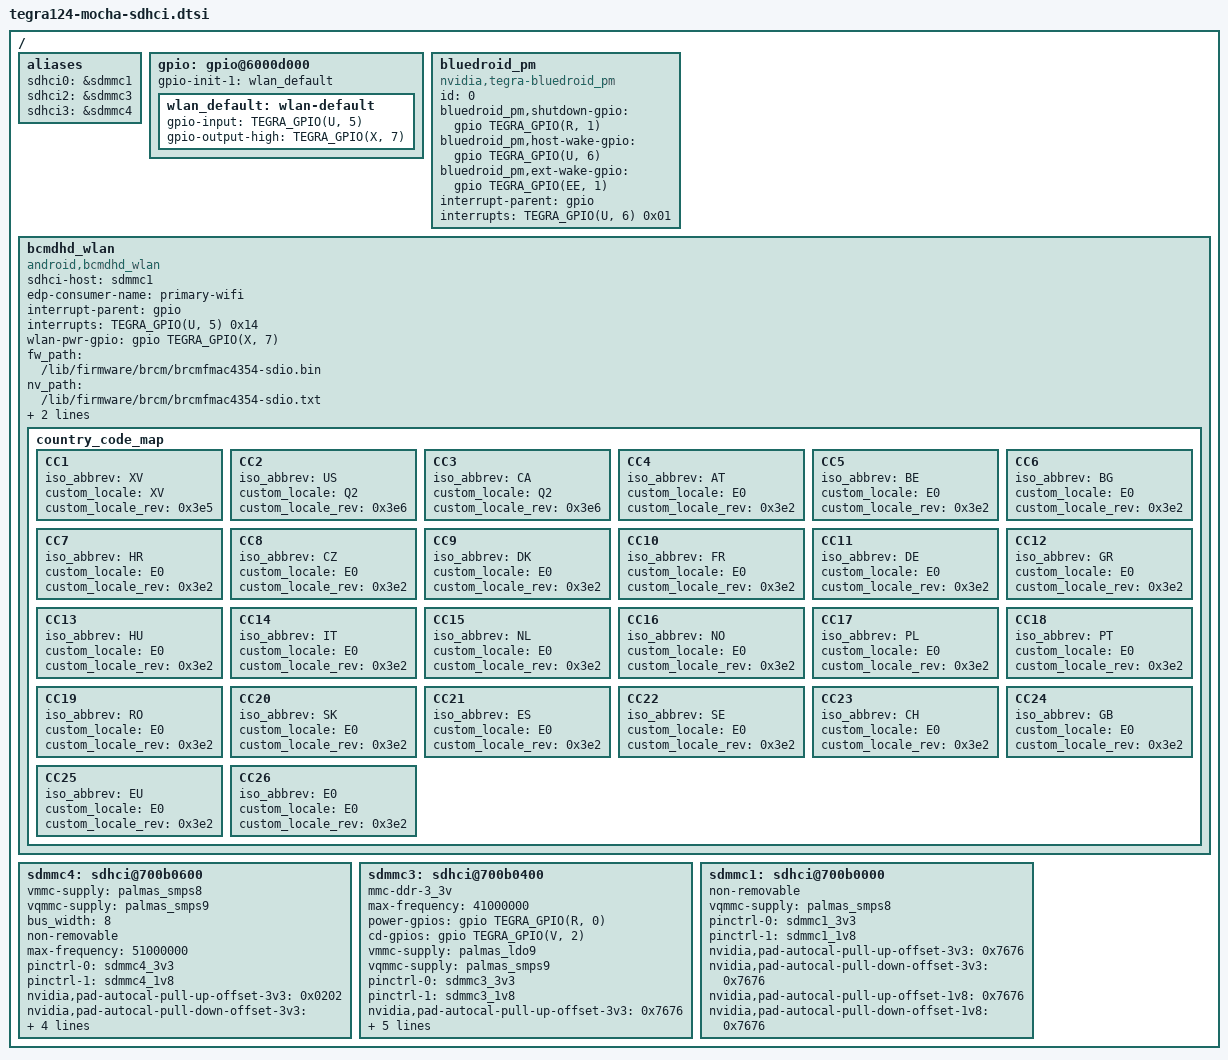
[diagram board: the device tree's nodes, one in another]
/*
 * arch/arm/boot/dts/tegra124-platforms/tegra124-mocha-sdhci.dtsi
 *
 * Copyright (c) 2018, Alexandrov Dmitry. All rights reserved.
 *
 * This program is free software; you can redistribute it and/or modify it
 * under the terms and conditions of the GNU General Public License,
 * version 2, as published by the Free Software Foundation.
 *
 * This program is distributed in the hope it will be useful, but WITHOUT
 * ANY WARRANTY; without even the implied warranty of MERCHANTABILITY or
 * FITNESS FOR A PARTICULAR PURPOSE.  See the GNU General Public License for
 * more details.
 *
 */
 
#include <dt-bindings/gpio/tegra-gpio.h>

/ {
	
 	aliases {
 		sdhci0 = &sdmmc1;
		sdhci2 = &sdmmc3;
		sdhci3 = &sdmmc4;
	};

	gpio: gpio@6000d000 {
		gpio-init-1 = <&wlan_default>;

		wlan_default: wlan-default {
			gpio-input = <
				TEGRA_GPIO(U, 5)
				>;
			gpio-output-high = <
				TEGRA_GPIO(X, 7)
				>;
		};
	};

	bluedroid_pm {
		compatible = "nvidia,tegra-bluedroid_pm";
		id = <0>;
		bluedroid_pm,shutdown-gpio = <&gpio TEGRA_GPIO(R, 1) 0>;
		bluedroid_pm,host-wake-gpio = <&gpio TEGRA_GPIO(U, 6) 0>;
		bluedroid_pm,ext-wake-gpio = <&gpio TEGRA_GPIO(EE, 1) 0>;
		interrupt-parent = <&gpio>;
		interrupts = <TEGRA_GPIO(U, 6) 0x01>;
	};

	bcmdhd_wlan {
		compatible = "android,bcmdhd_wlan";
		sdhci-host = <&sdmmc1>;
		edp-consumer-name = "primary-wifi";
		interrupt-parent = <&gpio>;
		interrupts = <TEGRA_GPIO(U, 5) 0x14>;
		wlan-pwr-gpio = <&gpio TEGRA_GPIO(X, 7) 0>;
		status = "okay";
		fw_path = "/lib/firmware/brcm/brcmfmac4354-sdio.bin";
		nv_path = "/lib/firmware/brcm/brcmfmac4354-sdio.txt";
		mac-address-file = "/lib/firmware/brcm/macaddr.txt";

		country_code_map {

			CC1 {
				iso_abbrev = "XV";
				custom_locale = "XV";
				custom_locale_rev = <0x3e5>;
			};

			CC2 {
				iso_abbrev = "US";
				custom_locale = "Q2";
				custom_locale_rev = <0x3e6>;
			};

			CC3 {
				iso_abbrev = "CA";
				custom_locale = "Q2";
				custom_locale_rev = <0x3e6>;
			};

			CC4 {
				iso_abbrev = "AT";
				custom_locale = "E0";
				custom_locale_rev = <0x3e2>;
			};

			CC5 {
				iso_abbrev = "BE";
				custom_locale = "E0";
				custom_locale_rev = <0x3e2>;
			};

			CC6 {
				iso_abbrev = "BG";
				custom_locale = "E0";
				custom_locale_rev = <0x3e2>;
			};

			CC7 {
				iso_abbrev = "HR";
				custom_locale = "E0";
				custom_locale_rev = <0x3e2>;
			};

			CC8 {
				iso_abbrev = "CZ";
				custom_locale = "E0";
				custom_locale_rev = <0x3e2>;
			};

			CC9 {
				iso_abbrev = "DK";
				custom_locale = "E0";
				custom_locale_rev = <0x3e2>;
			};

			CC10 {
				iso_abbrev = "FR";
				custom_locale = "E0";
				custom_locale_rev = <0x3e2>;
			};

			CC11 {
				iso_abbrev = "DE";
				custom_locale = "E0";
				custom_locale_rev = <0x3e2>;
			};

			CC12 {
				iso_abbrev = "GR";
				custom_locale = "E0";
				custom_locale_rev = <0x3e2>;
			};

			CC13 {
				iso_abbrev = "HU";
				custom_locale = "E0";
				custom_locale_rev = <0x3e2>;
			};

			CC14 {
				iso_abbrev = "IT";
				custom_locale = "E0";
				custom_locale_rev = <0x3e2>;
			};

			CC15 {
				iso_abbrev = "NL";
				custom_locale = "E0";
				custom_locale_rev = <0x3e2>;
			};

			CC16 {
				iso_abbrev = "NO";
				custom_locale = "E0";
				custom_locale_rev = <0x3e2>;
			};

			CC17 {
				iso_abbrev = "PL";
				custom_locale = "E0";
				custom_locale_rev = <0x3e2>;
			};

			CC18 {
				iso_abbrev = "PT";
				custom_locale = "E0";
				custom_locale_rev = <0x3e2>;
			};

			CC19 {
				iso_abbrev = "RO";
				custom_locale = "E0";
				custom_locale_rev = <0x3e2>;
			};

			CC20 {
				iso_abbrev = "SK";
				custom_locale = "E0";
				custom_locale_rev = <0x3e2>;
			};

			CC21 {
				iso_abbrev = "ES";
				custom_locale = "E0";
				custom_locale_rev = <0x3e2>;
			};

			CC22 {
				iso_abbrev = "SE";
				custom_locale = "E0";
				custom_locale_rev = <0x3e2>;
			};

			CC23 {
				iso_abbrev = "CH";
				custom_locale = "E0";
				custom_locale_rev = <0x3e2>;
			};

			CC24 {
				iso_abbrev = "GB";
				custom_locale = "E0";
				custom_locale_rev = <0x3e2>;
			};

			CC25 {
				iso_abbrev = "EU";
				custom_locale = "E0";
				custom_locale_rev = <0x3e2>;
			};

			CC26 {
				iso_abbrev = "E0";
				custom_locale = "E0";
				custom_locale_rev = <0x3e2>;
			};
		};
	};
	
	/* MMC */
 	sdmmc4: sdhci@700b0600 {
		vmmc-supply = <&palmas_smps8>;
		vqmmc-supply = <&palmas_smps9>;
		bus_width = <8>;
		non-removable;
		max-frequency = <51000000>;
		pinctrl-names = "sdmmc-3v3", "sdmmc-1v8";
		pinctrl-0 = <&sdmmc4_3v3>;
		pinctrl-1 = <&sdmmc4_1v8>;
		nvidia,pad-autocal-pull-up-offset-3v3 = <0x0202>;
		nvidia,pad-autocal-pull-down-offset-3v3 = <0x0202>;
		nvidia,pad-autocal-pull-up-offset-1v8 = <0x0202>;
		nvidia,pad-autocal-pull-down-offset-1v8 = <0x0202>;
		status = "okay";
 	};
	
	/* SDcard */
	sdmmc3: sdhci@700b0400 {
		mmc-ddr-3_3v;
		max-frequency = <41000000>;
 		power-gpios = <&gpio TEGRA_GPIO(R, 0) 0>;
 		cd-gpios = <&gpio TEGRA_GPIO(V, 2) 0>;
 		vmmc-supply = <&palmas_ldo9>;
		vqmmc-supply = <&palmas_smps9>;
		pinctrl-names = "sdmmc-3v3", "sdmmc-1v8";
		pinctrl-0 = <&sdmmc3_3v3>;
		pinctrl-1 = <&sdmmc3_1v8>;
		nvidia,pad-autocal-pull-up-offset-3v3 = <0x7676>;
		nvidia,pad-autocal-pull-down-offset-3v3 = <0x7676>;
		nvidia,pad-autocal-pull-up-offset-1v8 = <0x7676>;
		nvidia,pad-autocal-pull-down-offset-1v8 = <0x7676>;
		status = "okay";
	};
	
	/* Wi-Fi */
	sdmmc1: sdhci@700b0000 {
		non-removable;
		vqmmc-supply = <&palmas_smps8>;
		pinctrl-names = "sdmmc-3v3", "sdmmc-1v8";
		pinctrl-0 = <&sdmmc1_3v3>;
		pinctrl-1 = <&sdmmc1_1v8>;
		nvidia,pad-autocal-pull-up-offset-3v3 = <0x7676>;
		nvidia,pad-autocal-pull-down-offset-3v3 = <0x7676>;
		nvidia,pad-autocal-pull-up-offset-1v8 = <0x7676>;
		nvidia,pad-autocal-pull-down-offset-1v8 = <0x7676>;
 		status = "okay";
	};
};
